AUTOSAR XML (schema 4-2-2)
standard types defined: Boolean, Uint8, Uint16, Uint32, Sint16
package /DataTypes/ImplementationTypes
  13 x impl type:
    t_Temperature: compu {phys=raw*0.1-40 for raw -80..120; unit DegreeC}, range raw -80..120, implementation-data-type=Sint16, unit=DegreeC
    t_VehicleSpeed: compu {phys=raw*0.05625 for raw 0..240; unit Kmperh}, range raw 0..240, implementation-data-type=Sint16, unit=Kmperh
    t_UsageMode: compu {0=E_USGMODST_STANDBY, 3=E_USGMODST_COMFORT, 5=E_USGMODST_TOBEDRV, 7=E_USGMODST_DRV, 12=E_USGMODST_NOTUSED}, range raw 0..12, implementation-data-type=Uint8
    t_BatteryMode: compu {0=E_BATMODE_OFF, 1=E_BATMODE_IG, 2=E_BATMODE_ON}, range raw 0..2, implementation-data-type=Uint8
    t_HvacCtrReturn: compu {0=E_HVACCTR_ACCEPT, 1=E_HVACCTR_PARAMERROR, 2=E_HVACCTR_MODEERROR}, range raw 0..2, implementation-data-type=Uint8
    t_HvacOnOff: compu {0=E_HVACSW_NONE, 1=E_HVACSW_ON, 2=E_HVACSW_0FF}, range raw 0..2, implementation-data-type=Uint8
    t_HvacOperationMode: compu {0=E_HVACOP_NONE, 1=E_HVACOP_DEMIST, 2=E_HVACOP_HEAT, 3=E_HVACOP_REFRIG, 4=E_HVACOP_AUTO}, range raw 0..4, implementation-data-type=Uint8
    t_HvacCirculationMode: compu {0=E_HVACCIRC_NONE, 1=E_HVACCIRC_INT, 2=E_HVACCIRC_EXT}, range raw 0..2, implementation-data-type=Uint8
    t_HvacFanCtrMode: compu {0=E_HVACFANCTR_NONE, 1=E_HVACFANCTR_FACE, 2=E_HVACFANCTR_UP, 3=E_HVACFANCTR_DOWN}, range raw 0..3, implementation-data-type=Uint8
    t_MotorCtrCmd: compu {0=E_MOTORCTRCMD_NONE, 1=E_MOTORCTRCMD_OPEN, 2=E_MOTORCTRCMD_CLOSE}, range raw 0..2, implementation-data-type=Uint8
    t_MotorCtrErr: compu {0=E_MOTORCTRERR_ACCEPT, 1=E_MOTORCTRERR_DENIED}, range raw 0..1, implementation-data-type=Uint8
    t_MotorErr: category=STRUCTURE
      element OpenLoad: implementation-data-type=Boolean
      element Short2GND: implementation-data-type=Boolean
      element Short2BAT: implementation-data-type=Boolean
    t_VehicleMode: category=STRUCTURE
      element UsageMode: implementation-data-type=t_UsageMode
      element BatteryMode: implementation-data-type=t_BatteryMode
package /DataTypes/Units
  unit DegreeC: display-name=DegreeC
  unit Kmperh: display-name=Kmperh
package /PortInterfaces
  4 x sender receiver interface:
    VehicleConditions
      data FunctionInhibit: type=Boolean
      data MotorErrFlag: type=Boolean
      data SpeedLimited: type=Boolean
    MotorErr
      data LeftMotor: type=t_MotorErr
      data RightMotor: type=t_MotorErr
    VehicleMode
      data Data: type=t_VehicleMode
    GeneralInterface
      data Status: type=Boolean
  client server interface CockpitService
    4 x operation, all with possible-error=[CockpitService/E_OK, CockpitService/E_NOT_OK]:
      GetAmbientTemp
        arg Data: type=t_Temperature, direction=OUT, server-argument-impl-policy=USE-ARGUMENT-TYPE
      GetInteriorTemp
        arg Data: type=t_Temperature, direction=OUT, server-argument-impl-policy=USE-ARGUMENT-TYPE
      SetHvacCtrl
        6 x arg, all with server-argument-impl-policy=USE-ARGUMENT-TYPE:
          OnOff: type=t_HvacOnOff, direction=IN
          OperationMode: type=t_HvacOperationMode, direction=IN
          CirculationMode: type=t_HvacCirculationMode, direction=IN
          FanCtrMode: type=t_HvacFanCtrMode, direction=IN
          TargetTemp: type=t_Temperature, direction=IN
          ReturnCode: type=t_HvacCtrReturn, direction=OUT
      RefreshRequest
    error E_OK: error-code=0
    error E_NOT_OK: error-code=1
  client server interface MotorCtrService
    operation MoveRequest: possible-error=[MotorCtrService/E_OK, E_MOTOR_APPERROR]
      arg Cmd: type=t_MotorCtrCmd, direction=IN, server-argument-impl-policy=USE-ARGUMENT-TYPE
      arg Result: type=t_MotorCtrErr, direction=OUT, server-argument-impl-policy=USE-ARGUMENT-TYPE
    operation lastStopReason: possible-error=[MotorCtrService/E_OK, E_MOTOR_APPERROR]
      arg Result: type=Uint8, direction=OUT, server-argument-impl-policy=USE-ARGUMENT-TYPE
    operation MotorRunning: possible-error=[MotorCtrService/E_OK, E_MOTOR_APPERROR]
      arg Flag: type=Boolean, direction=INOUT, server-argument-impl-policy=USE-ARGUMENT-TYPE
    error E_OK: error-code=0
    error E_MOTOR_APPERROR: error-code=1
  client server interface DoorLockService
    operation LockRequest: possible-error=[DoorLockService/E_OK, DoorLockService/E_NOT_OK]
      arg Cmd: type=Uint8, direction=IN, server-argument-impl-policy=USE-ARGUMENT-TYPE
      arg Result: type=Uint8, direction=OUT, server-argument-impl-policy=USE-ARGUMENT-TYPE
    operation GetDoorStatus: possible-error=[DoorLockService/E_OK, DoorLockService/E_NOT_OK]
      arg Result: type=Uint8, direction=OUT, server-argument-impl-policy=USE-ARGUMENT-TYPE
    operation LookUpDoorCfg: possible-error=[DoorLockService/E_OK, DoorLockService/E_NOT_OK]
      arg IndexResult: type=Uint8, direction=INOUT, server-argument-impl-policy=USE-ARGUMENT-TYPE
      arg ErrCode: type=Uint8, direction=OUT, server-argument-impl-policy=USE-ARGUMENT-TYPE
    error E_OK: error-code=0
    error E_NOT_OK: error-code=1
package /ComponentTypes
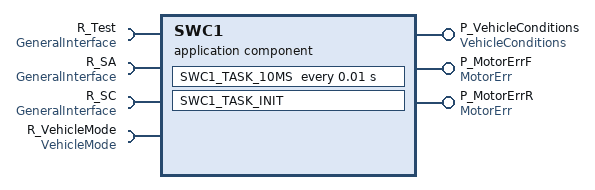
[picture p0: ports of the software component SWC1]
  application sw component type SWC1
    provide port P_VehicleConditions: provided-com-specs=[data-element=FunctionInhibit, data-element=MotorErrFlag, data-element=SpeedLimited], provided-interface=VehicleConditions
    provide port P_MotorErrF: provided-com-specs=[data-element=LeftMotor, data-element=RightMotor], provided-interface=MotorErr
    provide port P_MotorErrR: provided-com-specs=[data-element=LeftMotor, data-element=RightMotor], provided-interface=MotorErr
    4 x require port:
      R_Test: required-interface=GeneralInterface
      R_SA: required-interface=GeneralInterface
      R_SC: required-interface=GeneralInterface
      R_VehicleMode: required-interface=VehicleMode
    behavior SWC1_InternalBehavior
      init event IT_SWC1_TASK_INIT: start-on-event=SWC1_TASK_INIT
      timing event TMT_SWC1_TASK_10MS: start-on-event=SWC1_TASK_10MS, period=0.01
      port-api-options:
        enable-take-address=false, indirect-api=false, port=P_MotorErrF
        enable-take-address=false, indirect-api=false, port=SWC1/P_MotorErrR
        enable-take-address=false, indirect-api=false, port=SWC1/P_VehicleConditions
        enable-take-address=false, indirect-api=false, port=R_SA
        enable-take-address=false, indirect-api=false, port=SWC1/R_SC
        enable-take-address=false, indirect-api=false, port=R_Test
        enable-take-address=false, indirect-api=false, port=SWC1/R_VehicleMode
      runnable SWC1_TASK_INIT
      runnable SWC1_TASK_10MS
        data-receive-point-by-arguments:
          4 x access:
            REC_R_Test_Status: accessed-variable=R_Test.Status
            REC_R_SA_Status: accessed-variable=R_SA.Status
            REC_R_SC_Status: accessed-variable=R_SC.Status
            REC_R_VehicleMode_Data: accessed-variable=R_VehicleMode.Data
        data-send-points:
          7 x access:
            SEND_P_VehicleConditions_FunctionInhibit: accessed-variable=P_VehicleConditions.FunctionInhibit
            SEND_P_VehicleConditions_MotorErrFlag: accessed-variable=P_VehicleConditions.MotorErrFlag
            SEND_P_VehicleConditions_SpeedLimited: accessed-variable=P_VehicleConditions.SpeedLimited
            SEND_P_MotorErrF_LeftMotor: accessed-variable=P_MotorErrF.LeftMotor
            SEND_P_MotorErrF_RightMotor: accessed-variable=P_MotorErrF.RightMotor
            SEND_P_MotorErrR_LeftMotor: accessed-variable=P_MotorErrR.LeftMotor
            SEND_P_MotorErrR_RightMotor: accessed-variable=P_MotorErrR.RightMotor
  swc implementation SWC1_Implementation: behavior=SWC1_InternalBehavior
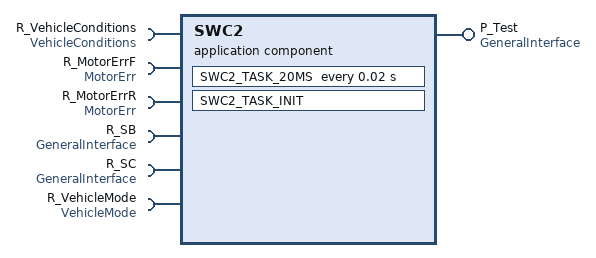
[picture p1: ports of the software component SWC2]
  application sw component type SWC2
    provide port P_Test: nonqueued-sender-com-spec=data-element=Status, provided-interface=GeneralInterface
    6 x require port:
      R_VehicleConditions: required-interface=VehicleConditions
      R_MotorErrF: required-interface=MotorErr
      R_MotorErrR: required-interface=MotorErr
      R_SB: required-interface=GeneralInterface
      R_SC: required-interface=GeneralInterface
      R_VehicleMode: required-interface=VehicleMode
    behavior SWC2_InternalBehavior
      init event IT_SWC2_TASK_INIT: start-on-event=SWC2_TASK_INIT
      timing event TMT_SWC2_TASK_20MS: start-on-event=SWC2_TASK_20MS, period=0.02
      port-api-options:
        enable-take-address=false, indirect-api=false, port=SWC2/P_Test
        enable-take-address=false, indirect-api=false, port=SWC2/R_MotorErrF
        enable-take-address=false, indirect-api=false, port=R_MotorErrR
        enable-take-address=false, indirect-api=false, port=R_SB
        enable-take-address=false, indirect-api=false, port=SWC2/R_SC
        enable-take-address=false, indirect-api=false, port=R_VehicleConditions
        enable-take-address=false, indirect-api=false, port=SWC2/R_VehicleMode
      runnable SWC2_TASK_INIT
      runnable SWC2_TASK_20MS
        data-receive-point-by-arguments:
          10 x access:
            REC_R_VehicleConditions_FunctionInhibit: accessed-variable=R_VehicleConditions.FunctionInhibit
            REC_R_VehicleConditions_MotorErrFlag: accessed-variable=R_VehicleConditions.MotorErrFlag
            REC_R_VehicleConditions_SpeedLimited: accessed-variable=R_VehicleConditions.SpeedLimited
            REC_R_MotorErrF_LeftMotor: accessed-variable=R_MotorErrF.LeftMotor
            REC_R_MotorErrF_RightMotor: accessed-variable=R_MotorErrF.RightMotor
            REC_R_MotorErrR_LeftMotor: accessed-variable=R_MotorErrR.LeftMotor
            REC_R_MotorErrR_RightMotor: accessed-variable=R_MotorErrR.RightMotor
            REC_R_SB_Status: accessed-variable=R_SB.Status
            REC_R_SC_Status: accessed-variable=R_SC.Status
            REC_R_VehicleMode_Data: accessed-variable=R_VehicleMode.Data
        data-send-points:
          access SEND_P_Test_Status: accessed-variable=P_Test.Status
  swc implementation SWC2_Implementation: behavior=SWC2_InternalBehavior
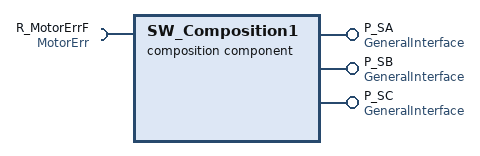
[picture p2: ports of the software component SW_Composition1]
  composition sw component type SW_Composition1
    provide port P_SA: nonqueued-sender-com-spec=data-element=Status, provided-interface=GeneralInterface
    provide port P_SB: nonqueued-sender-com-spec=data-element=Status, provided-interface=GeneralInterface
    provide port P_SC: nonqueued-sender-com-spec=data-element=Status, provided-interface=GeneralInterface
    require port R_MotorErrF: required-interface=MotorErr
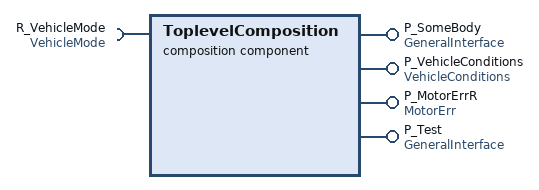
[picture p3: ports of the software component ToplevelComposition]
  composition sw component type ToplevelComposition
    4 x provide port:
      P_SomeBody: nonqueued-sender-com-spec=data-element=Status, provided-interface=GeneralInterface
      P_VehicleConditions: provided-com-specs=[data-element=FunctionInhibit, data-element=MotorErrFlag, data-element=SpeedLimited], provided-interface=VehicleConditions
      P_MotorErrR: provided-com-specs=[data-element=LeftMotor, data-element=RightMotor], provided-interface=MotorErr
      P_Test: nonqueued-sender-com-spec=data-element=Status, provided-interface=GeneralInterface
    require port R_VehicleMode: required-interface=VehicleMode
    component SWC1: type=SWC1
    component SWC2: type=SWC2
    component SW_Composition1: type=SW_Composition1
    connect SWC1.P_VehicleConditions -> SWC2.R_VehicleConditions
    connect SWC1.P_MotorErrF -> SWC2.R_MotorErrF
    connect SWC1.P_MotorErrF -> SW_Composition1.R_MotorErrF
    connect SWC1.P_MotorErrR -> SWC2.R_MotorErrR
    connect SWC2.P_Test -> SWC1.R_Test
    connect SW_Composition1.P_SA -> SWC1.R_SA
    connect SW_Composition1.P_SB -> SWC2.R_SB
    connect SW_Composition1.P_SC -> SWC2.R_SC
    connect SW_Composition1.P_SC -> SWC1.R_SC
    delegate SWC1.P_VehicleConditions <-> outer port ToplevelComposition/P_VehicleConditions
    delegate SWC1.P_MotorErrR <-> outer port ToplevelComposition/P_MotorErrR
    delegate SWC2.P_Test <-> outer port ToplevelComposition/P_Test
    delegate SWC1.R_VehicleMode <-> outer port ToplevelComposition/R_VehicleMode
    delegate SWC2.R_VehicleMode <-> outer port ToplevelComposition/R_VehicleMode
